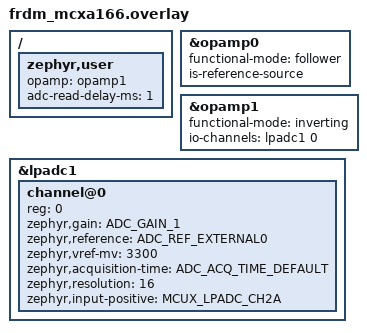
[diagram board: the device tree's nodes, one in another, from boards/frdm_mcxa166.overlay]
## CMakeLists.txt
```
# Copyright 2025 NXP
# SPDX-License-Identifier: Apache-2.0

cmake_minimum_required(VERSION 3.28.0)

find_package(Zephyr REQUIRED HINTS $ENV{ZEPHYR_BASE})
project(output_measure)

FILE(GLOB app_sources src/*.c)
target_sources(app PRIVATE ${app_sources})
```

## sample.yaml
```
# Copyright 2025 NXP
# SPDX-License-Identifier: Apache-2.0

sample:
  name: OPAMP output measurement sample
tests:
  sample.drivers.opamp.output_measure:
    tags: opamp
    depends_on: opamp
    harness: console
    harness_config:
      type: multi_line
      regex:
        - "OPAMP output \\(@gain: (?:\\d+|\\d+/\\d+)\\) is: -?\\d+\\(mv\\)"
    platform_allow:
      - frdm_mcxa156
      - frdm_mcxa346
      - frdm_mcxa366
      - frdm_mcxn947/mcxn947/cpu0
      - lpcxpresso55s36
      - nucleo_g474re/stm32g474xx
```

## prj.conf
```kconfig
# Copyright 2025 NXP
# SPDX-License-Identifier: Apache-2.0

CONFIG_ADC=y
CONFIG_OPAMP=y

CONFIG_LOG=y
# CONFIG_LOG_BUFFER_SIZE=4096
# CONFIG_OPAMP_LOG_LEVEL_DBG=y
```

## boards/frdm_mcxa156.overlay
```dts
/*
 * Copyright 2025 NXP
 *
 * SPDX-License-Identifier: Apache-2.0
 */

#include <zephyr/dt-bindings/adc/adc.h>
#include <zephyr/dt-bindings/adc/mcux-lpadc.h>

/ {
	zephyr,user {
		opamp = <&opamp0>;
		adc-read-delay-ms = <1>;
		io-channels = <&lpadc0 0>;
	};
};

&opamp0 {
	enable-measure-output;
	functional-mode = "differential";
	programmable-gain = "OPAMP_GAIN_1",
			    "OPAMP_GAIN_2",
			    "OPAMP_GAIN_4";
};

&lpadc0 {
	#address-cells = <1>;
	#size-cells = <0>;

	channel@0 {
		reg = <0>;
		zephyr,gain = "ADC_GAIN_1";
		zephyr,reference = "ADC_REF_EXTERNAL0";
		zephyr,vref-mv = <3300>;
		zephyr,acquisition-time = <ADC_ACQ_TIME_DEFAULT>;
		zephyr,resolution = <16>;
		/* LPADC0 CH3A is internally connected to the operational amplifier output. */
		zephyr,input-positive = <MCUX_LPADC_CH3A>;
	};
};
```

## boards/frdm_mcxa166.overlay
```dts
/*
 * Copyright 2025 NXP
 *
 * SPDX-License-Identifier: Apache-2.0
 */

#include <zephyr/dt-bindings/adc/adc.h>
#include <zephyr/dt-bindings/adc/mcux-lpadc.h>

/ {
	zephyr,user {
		opamp = <&opamp1>;
		adc-read-delay-ms = <1>;
	};
};

/* OPAMP is in follower mode, and its output is Vref of OPAMP1/2/3. */
&opamp0 {
	functional-mode = "follower";
	is-reference-source;
};

&opamp1 {
	functional-mode = "inverting";
	io-channels = <&lpadc1 0>;
};

&lpadc1 {
	#address-cells = <1>;
	#size-cells = <0>;

	channel@0 {
		reg = <0>;
		zephyr,gain = "ADC_GAIN_1";
		zephyr,reference = "ADC_REF_EXTERNAL0";
		zephyr,vref-mv = <3300>;
		zephyr,acquisition-time = <ADC_ACQ_TIME_DEFAULT>;
		zephyr,resolution = <16>;
		/* LPADC1 CH2A is internally connected to the OPAMP1 output. */
		zephyr,input-positive = <MCUX_LPADC_CH2A>;
	};
};
```

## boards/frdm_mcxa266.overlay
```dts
/*
 * Copyright 2025 NXP
 *
 * SPDX-License-Identifier: Apache-2.0
 */

#include <zephyr/dt-bindings/adc/adc.h>
#include <zephyr/dt-bindings/adc/mcux-lpadc.h>

/ {
	zephyr,user {
		opamp = <&opamp1>;
		adc-read-delay-ms = <1>;
		io-channels = <&lpadc1 0>;
	};
};

/* OPAMP is in follower mode, and its output is Vref of OPAMP1/2/3 */
&opamp0 {
	functional-mode = "follower";
	is-reference-source;
	compensation-capcitor = <0>;
};

&opamp1 {
	functional-mode = "inverting";
	compensation-capcitor = <2>;
};

&lpadc1 {
	#address-cells = <1>;
	#size-cells = <0>;

	channel@0 {
		reg = <0>;
		zephyr,gain = "ADC_GAIN_1";
		zephyr,reference = "ADC_REF_EXTERNAL0";
		zephyr,vref-mv = <3300>;
		zephyr,acquisition-time = <ADC_ACQ_TIME_DEFAULT>;
		zephyr,resolution = <16>;
		/* LPADC1 CH2A is internally connected to the OPAMP1 output. */
		zephyr,input-positive = <MCUX_LPADC_CH2A>;
	};
};
```

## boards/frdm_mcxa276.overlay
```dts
/*
 * Copyright 2025 NXP
 *
 * SPDX-License-Identifier: Apache-2.0
 */

#include <zephyr/dt-bindings/adc/adc.h>
#include <zephyr/dt-bindings/adc/mcux-lpadc.h>

/ {
	zephyr,user {
		opamp = <&opamp1>;
		adc-read-delay-ms = <1>;
	};
};

/* OPAMP is in follower mode, and its output is Vref of OPAMP1/2/3 */
&opamp0 {
	functional-mode = "follower";
	is-reference-source;
};

&opamp1 {
	functional-mode = "inverting";
	io-channels = <&lpadc1 0>;
};

&lpadc1 {
	#address-cells = <1>;
	#size-cells = <0>;

	channel@0 {
		reg = <0>;
		zephyr,gain = "ADC_GAIN_1";
		zephyr,reference = "ADC_REF_EXTERNAL0";
		zephyr,vref-mv = <3300>;
		zephyr,acquisition-time = <ADC_ACQ_TIME_DEFAULT>;
		zephyr,resolution = <16>;
		/* LPADC1 CH2A is internally connected to the OPAMP1 output. */
		zephyr,input-positive = <MCUX_LPADC_CH2A>;
	};
};
```

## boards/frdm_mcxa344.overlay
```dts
/*
 * Copyright 2026 NXP
 *
 * SPDX-License-Identifier: Apache-2.0
 */

#include <zephyr/dt-bindings/adc/adc.h>
#include <zephyr/dt-bindings/adc/mcux-lpadc.h>

/ {
	zephyr,user {
		opamp = <&opamp0>;
		adc-read-delay-ms = <1>;
		io-channels = <&lpadc0 0>;
	};
};

&opamp0 {
	functional-mode = "differential";
};

&lpadc0 {
	#address-cells = <1>;
	#size-cells = <0>;

	channel@0 {
		reg = <0>;
		zephyr,gain = "ADC_GAIN_1";
		zephyr,reference = "ADC_REF_EXTERNAL0";
		zephyr,vref-mv = <3300>;
		zephyr,acquisition-time = <ADC_ACQ_TIME_DEFAULT>;
		zephyr,resolution = <16>;
		/* LPADC0 CH2A is internally connected to the operational amplifier output. */
		zephyr,input-positive = <MCUX_LPADC_CH2A>;
	};
};
```

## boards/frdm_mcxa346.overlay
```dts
/*
 * Copyright 2025 NXP
 *
 * SPDX-License-Identifier: Apache-2.0
 */

#include <zephyr/dt-bindings/adc/adc.h>
#include <zephyr/dt-bindings/adc/mcux-lpadc.h>

/ {
	zephyr,user {
		opamp = <&opamp1>;
		adc-read-delay-ms = <1>;
	};
};

/* OPAMP is in follower mode, and its output is Vref of OPAMP1/2/3. */
&opamp0 {
	functional-mode = "follower";
	is-reference-source;
	compensation-capcitor = <0>;
};

&opamp1 {
	functional-mode = "inverting";
	io-channels = <&lpadc1 0>;
	compensation-capcitor = <2>;
};

&lpadc1 {
	#address-cells = <1>;
	#size-cells = <0>;

	channel@0 {
		reg = <0>;
		zephyr,gain = "ADC_GAIN_1";
		zephyr,reference = "ADC_REF_EXTERNAL0";
		zephyr,vref-mv = <3300>;
		zephyr,acquisition-time = <ADC_ACQ_TIME_DEFAULT>;
		zephyr,resolution = <16>;
		/* LPADC1 CH2A is internally connected to the OPAMP1 output. */
		zephyr,input-positive = <MCUX_LPADC_CH2A>;
	};
};
```

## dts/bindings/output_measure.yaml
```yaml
# Copyright 2025 NXP
# SPDX-License-Identifier: Apache-2.0

description: |
    This binding provides resources required to build and run the
    samples/drivers/opamp/output_measure in Zephyr.

compatible: "opamp-output-measure"

properties:
  opamp:
    type: phandles
    required: true
    description: |
      Indicates opamp to be tested.

  io-channels:
    type: phandle-array
    required: true
    description: |
      Indicates ADC channels to be used.

  adc-read-delay-ms:
    type: int
    default: 0
    description: |
      Indicates delay (in ms) between voltage set and ADC read.
```

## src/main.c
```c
/*
 * Copyright 2025 NXP
 *
 * SPDX-License-Identifier: Apache-2.0
 */

#include <stdio.h>
#include <zephyr/device.h>
#include <zephyr/devicetree.h>
#include <zephyr/drivers/adc.h>
#include <zephyr/drivers/opamp.h>

#define OPAMP_SUPPORT_PROGRAMMABLE_GAIN					\
	DT_NODE_HAS_PROP(DT_PHANDLE(DT_PATH(zephyr_user), opamp),	\
			programmable_gain)

#if OPAMP_SUPPORT_PROGRAMMABLE_GAIN
static const enum opamp_gain gain[] = {
	DT_FOREACH_PROP_ELEM_SEP(DT_PHANDLE(DT_PATH(zephyr_user), opamp),
				programmable_gain, DT_ENUM_IDX_BY_IDX, (,))
};
uint8_t size = ARRAY_SIZE(gain);
#else
uint8_t size;
#endif

const static char *opamp_gain2str[] = {
	[OPAMP_GAIN_1_7] = "1/7",
	[OPAMP_GAIN_1_3] = "1/3",
	[OPAMP_GAIN_1] = "1",
	[OPAMP_GAIN_5_3] = "5/3",
	[OPAMP_GAIN_2] = "2",
	[OPAMP_GAIN_11_5] = "11/5",
	[OPAMP_GAIN_3] = "3",
	[OPAMP_GAIN_4] = "4",
	[OPAMP_GAIN_13_3] = "13/3",
	[OPAMP_GAIN_7] = "7",
	[OPAMP_GAIN_8] = "8",
	[OPAMP_GAIN_15] = "15",
	[OPAMP_GAIN_16] = "16",
	[OPAMP_GAIN_31] = "31",
	[OPAMP_GAIN_32] = "32",
	[OPAMP_GAIN_33] = "33",
	[OPAMP_GAIN_63] = "63",
	[OPAMP_GAIN_64] = "64",
};

static int device_initialize(const struct adc_dt_spec *adc_channel,
			const struct device *opamp_dev,
			struct adc_sequence *seq)
{
	int ret;

	if (!adc_is_ready_dt(adc_channel)) {
		printk("ADC device %s is not ready\n", adc_channel->dev->name);
		return -ENODEV;
	}

	if (!device_is_ready(opamp_dev)) {
		printk("OPAMP device %s is not ready\n", opamp_dev->name);
		return -ENODEV;
	}

	ret = adc_channel_setup_dt(adc_channel);
	if (ret < 0) {
		printk("ADC channel could not be set up with code (%d)\n", ret);
		return ret;
	}

	ret = adc_sequence_init_dt(adc_channel, seq);
	if (ret < 0) {
		printk("ADC sequence initialize failed with code (%d)\n", ret);
		return ret;
	}

	return 0;
}

static int read_opamp_output(const struct adc_dt_spec *adc_channel,
			struct adc_sequence *seq,
			int32_t *sample_buffer)
{
	int ret;
	int32_t adc_read_delay_ms = DT_PROP(DT_PATH(zephyr_user), adc_read_delay_ms);

	if (adc_read_delay_ms > 0) {
		k_msleep(adc_read_delay_ms);
	}

	ret = adc_read_dt(adc_channel, seq);
	if (ret < 0) {
		printk("ADC read failed with code (%d)\n", ret);
		return ret;
	}

	ret = adc_raw_to_millivolts(adc_channel->vref_mv,
				adc_channel->channel_cfg.gain,
				adc_channel->resolution,
				sample_buffer);

	if (ret < 0) {
		printk("Convert to millivolts failed with code (%d)\n", ret);
		return ret;
	}

	return 0;
}

int main(void)
{
	static const struct adc_dt_spec adc_channel =
		ADC_DT_SPEC_GET(DT_PATH(zephyr_user));
	static const struct device *opamp_dev =
		DEVICE_DT_GET(DT_PHANDLE(DT_PATH(zephyr_user), opamp));
	static int32_t sample_buffer;
	int ret;

	struct adc_sequence sequence = {
		.buffer = &sample_buffer,
		.buffer_size = sizeof(sample_buffer),
		.calibrate = true,
	};

	ret = device_initialize(&adc_channel, opamp_dev, &sequence);
	if (ret < 0) {
		printk("Initialization failed with code (%d)\n", ret);
		return 0;
	}

	const char *gain_str = "default";

	do {
#if OPAMP_SUPPORT_PROGRAMMABLE_GAIN
		/* For OPAMPs which support programmable gain, retrieve the gain array. */
		ret = opamp_set_gain(opamp_dev, gain[size - 1]);
		if (ret < 0) {
			printk("OPAMP gain set failed with code (%d)\n", ret);
			return 0;
		}
		gain_str = opamp_gain2str[gain[size - 1]];
		size--;
#else
		/* Avoid compilation error on platforms without programmable gain. */
		ARG_UNUSED(opamp_gain2str);
#endif
		ret = read_opamp_output(&adc_channel, &sequence, &sample_buffer);
		if (ret < 0) {
			printk("OPAMP output read failed with code (%d)\n", ret);
			return 0;
		}

		printk("OPAMP output (@gain: %s) is: %d(mv)\n", gain_str, sample_buffer);
	} while (size);

	return 0;
}
```

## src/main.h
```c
/*
 * Copyright 2025 NXP
 *
 * SPDX-License-Identifier: Apache-2.0
 */

#ifndef MAIN_H
#define MAIN_H

#include <zephyr/drivers/opamp.h>

#define OPAMP_SUPPORT_PROGRAMMABLE_GAIN				\
	DT_PROP_OR(DT_PHANDLE(DT_PATH(zephyr_user), opamp),	\
		support_programmable_gain, 0)

#if OPAMP_SUPPORT_PROGRAMMABLE_GAIN
#if defined(CONFIG_BOARD_FRDM_MCXN947) ||	\
	defined(CONFIG_BOARD_FRDM_MCXA156) ||	\
	defined(CONFIG_BOARD_LPCXPRESSO55S36)
static const enum opamp_gain test_gain[] = {
	OPAMP_GAIN_1, OPAMP_GAIN_2, OPAMP_GAIN_4
};
#endif

#endif

#endif /* MAIN_H */
```
